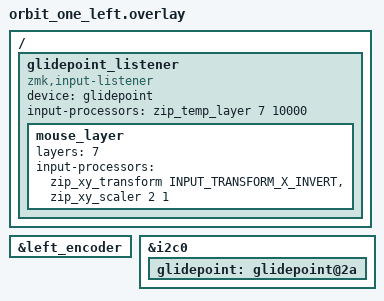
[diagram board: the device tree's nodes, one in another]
#include "orbit_one.dtsi"

/ {
     // pointing device
    glidepoint_listener {
        compatible = "zmk,input-listener";
        device = <&glidepoint>;
        input-processors = <&zip_temp_layer 7 10000>;

        mouse_layer {
          layers = <7>;

          input-processors = <&zip_xy_transform INPUT_TRANSFORM_X_INVERT>,<&zip_xy_scaler 2 1>;
        };
    };
};

&left_encoder {
    status = "okay";
};

&i2c0 {
    status = "okay";

    glidepoint: glidepoint@2a {
        status = "okay";
    };
};

